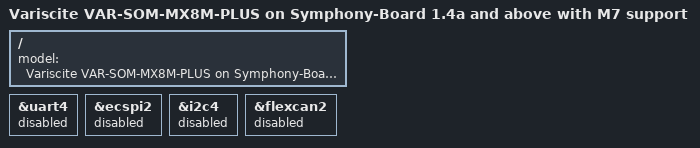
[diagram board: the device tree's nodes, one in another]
// SPDX-License-Identifier: (GPL-2.0+ OR MIT)
/*
 * Copyright 2019 NXP
 * Copyright 2020-2021 Variscite Ltd.
 */

#include "imx8mp-var-som-symphony.dts"
#include "imx8mp-var-common-m7.dtsi"

/ {
	model = "Variscite VAR-SOM-MX8M-PLUS on Symphony-Board 1.4a and above with M7 support";
};

/*
 * ATTENTION: M7 may use IPs like below
 * ECSPI2, I2C4, UART4, PWM2, SDMA1, FLEXCAN2
 */

&uart4 {
	status = "disabled";
};

&ecspi2 {
	status = "disabled";
};

&i2c4 {
	status = "disabled";
};

&flexcan2 {
	status = "disabled";
};
